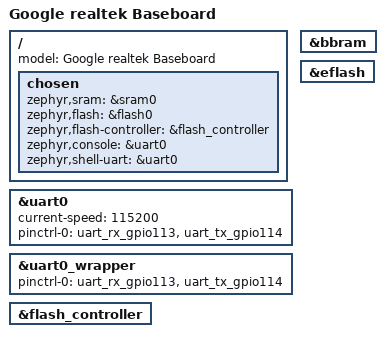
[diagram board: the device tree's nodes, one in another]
/* Copyright 2025 The ChromiumOS Authors
 * Use of this source code is governed by a BSD-style license that can be
 * found in the LICENSE file.
 */

#include <cros/realtek/realtek.dtsi>
#include <dt-bindings/gpio_defines.h>
#include <dt-bindings/gpio/realtek-gpio.h>
#include <realtek/ec/rts5912-pinctrl.dtsi>

/ {
	model = "Google realtek Baseboard";

	chosen {
		zephyr,sram = &sram0;
		zephyr,flash = &flash0;
		zephyr,flash-controller = &flash_controller;
		zephyr,console = &uart0;
		zephyr,shell-uart = &uart0;
	};
};

&uart0 {
	status = "okay";
	current-speed = <115200>;
	pinctrl-0 = <&uart_rx_gpio113
			&uart_tx_gpio114>;
	pinctrl-names = "default";
};

&uart0_wrapper {
	status = "okay";
	pinctrl-0 = <&uart_rx_gpio113 &uart_tx_gpio114>;
	pinctrl-names = "default";
};

&bbram {
	status = "okay";
};

&eflash {
	status = "okay";
};

&flash_controller {
	status = "okay";
};
